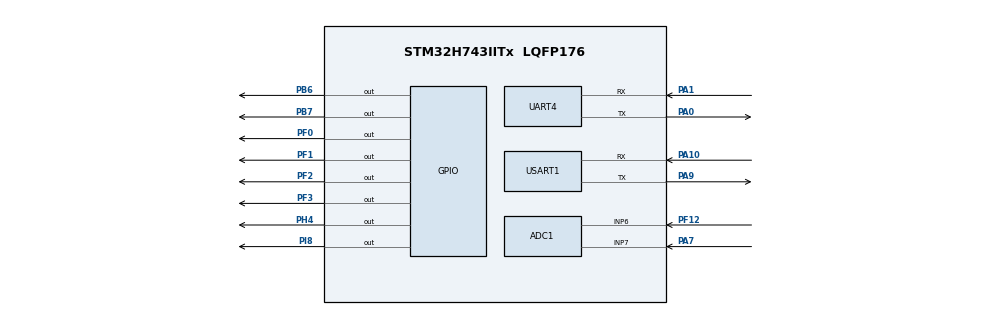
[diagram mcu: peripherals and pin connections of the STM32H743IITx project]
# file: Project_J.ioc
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ADC1.Channel-2\#ChannelRegularConversion=ADC_CHANNEL_6
ADC1.Channel-3\#ChannelRegularConversion=ADC_CHANNEL_7
ADC1.ContinuousConvMode=DISABLE
ADC1.DiscontinuousConvMode=ENABLE
ADC1.NbrOfConversion=2
ADC1.NbrOfConversionFlag=1
ADC1.NbrOfDiscConversion=1
ADC1.OffsetNumber-2\#ChannelRegularConversion=ADC_OFFSET_NONE
ADC1.OffsetNumber-3\#ChannelRegularConversion=ADC_OFFSET_NONE
ADC1.OffsetSignedSaturation-2\#ChannelRegularConversion=DISABLE
ADC1.OffsetSignedSaturation-3\#ChannelRegularConversion=DISABLE
ADC1.Rank-2\#ChannelRegularConversion=1
ADC1.Rank-3\#ChannelRegularConversion=2
ADC1.SamplingTime-2\#ChannelRegularConversion=ADC_SAMPLETIME_1CYCLE_5
ADC1.SamplingTime-3\#ChannelRegularConversion=ADC_SAMPLETIME_1CYCLE_5
ADC1.master=1
ADC3.Channel-1\#ChannelRegularConversion=ADC_CHANNEL_TEMPSENSOR
ADC3.Channel-2\#ChannelRegularConversion=ADC_CHANNEL_VBAT
ADC3.ContinuousConvMode=DISABLE
ADC3.DiscontinuousConvMode=ENABLE
ADC3.NbrOfConversion=2
ADC3.NbrOfConversionFlag=1
ADC3.NbrOfDiscConversion=1
ADC3.OffsetNumber-1\#ChannelRegularConversion=ADC_OFFSET_NONE
ADC3.OffsetNumber-2\#ChannelRegularConversion=ADC_OFFSET_NONE
ADC3.OffsetSignedSaturation-1\#ChannelRegularConversion=DISABLE
ADC3.OffsetSignedSaturation-2\#ChannelRegularConversion=DISABLE
ADC3.Rank-1\#ChannelRegularConversion=1
ADC3.Rank-2\#ChannelRegularConversion=2
ADC3.SamplingTime-1\#ChannelRegularConversion=ADC_SAMPLETIME_1CYCLE_5
ADC3.SamplingTime-2\#ChannelRegularConversion=ADC_SAMPLETIME_1CYCLE_5
CORTEX_M7.CPU_DCache=Enabled
CORTEX_M7.CPU_ICache=Enabled
Mcu.Family=STM32H7
Mcu.Name=STM32H743IITx
Mcu.Package=LQFP176
NVIC.PriorityGroup=NVIC_PRIORITYGROUP_4
NVIC.TIM15_IRQn=true\:14\:0\:true\:false\:true\:true\:true\:true
NVIC.TIM16_IRQn=true\:12\:0\:true\:false\:true\:true\:true\:true
NVIC.TIM17_IRQn=true\:13\:0\:true\:false\:true\:true\:true\:true
PA0.GPIO_Speed=GPIO_SPEED_FREQ_VERY_HIGH
PA0.Mode=Asynchronous
PA0.Signal=UART4_TX
PA1.GPIO_Speed=GPIO_SPEED_FREQ_VERY_HIGH
PA1.Mode=Asynchronous
PA1.Signal=UART4_RX
PA10.GPIO_Speed=GPIO_SPEED_FREQ_VERY_HIGH
PA10.Mode=Asynchronous
PA10.Signal=USART1_RX
PA13\ (JTMS/SWDIO).Mode=Serial_Wire
PA13\ (JTMS/SWDIO).Signal=DEBUG_JTMS-SWDIO
PA14\ (JTCK/SWCLK).Mode=Serial_Wire
PA14\ (JTCK/SWCLK).Signal=DEBUG_JTCK-SWCLK
PA7.Signal=ADCx_INP7
PA9.GPIO_Speed=GPIO_SPEED_FREQ_VERY_HIGH
PA9.Mode=Asynchronous
PA9.Signal=USART1_TX
PB6.Signal=GPIO_Output
PB7.Signal=GPIO_Output
PF0.Signal=GPIO_Output
PF1.Signal=GPIO_Output
PF12.Mode=IN6-Single-Ended
PF12.Signal=ADC1_INP6
PF2.Signal=GPIO_Output
PF3.Signal=GPIO_Output
PH4.Signal=GPIO_Output
PI8.Signal=GPIO_Output
ProjectManager.HeapSize=0x200
ProjectManager.StackSize=0x400
ProjectManager.TargetToolchain=Makefile
RCC.ADCFreq_Value=75000000
RCC.APB1Freq_Value=120000000
RCC.APB2Freq_Value=120000000
RCC.APB3Freq_Value=120000000
RCC.APB4Freq_Value=120000000
RCC.CortexFreq_Value=480000000
RCC.D1PPRE=RCC_APB3_DIV2
RCC.D2PPRE1=RCC_APB1_DIV2
RCC.D2PPRE2=RCC_APB2_DIV2
RCC.D3PPRE=RCC_APB4_DIV2
RCC.DIVM1=1
RCC.DIVM2=1
RCC.DIVM3=1
RCC.DIVN1=240
RCC.DIVN2=37
RCC.DIVN3=240
RCC.HCLKFreq_Value=240000000
RCC.HPRE=RCC_HCLK_DIV2
RCC.PLL2FRACN=4096
RCC.PLLSourceVirtual=RCC_PLLSOURCE_CSI
RCC.SYSCLKFreq_VALUE=480000000
RCC.SYSCLKSource=RCC_SYSCLKSOURCE_PLLCLK
RCC.USBFreq_Value=480000000
SH.ADCx_INP7.0=ADC1_INP7,IN7-Single-Ended
TIM15.Period=9999
TIM15.Prescaler=239
TIM16.Channel=TIM_CHANNEL_1
TIM16.Period=9
TIM16.Prescaler=23
TIM17.Channel=TIM_CHANNEL_1
TIM17.Period=999
TIM17.Prescaler=239
USART1.VirtualMode-Asynchronous=VM_ASYNC
VP_ADC3_TempSens_Input.Mode=IN-TempSens
VP_ADC3_Vbat_Input.Mode=IN-Vbat
VP_TIM15_VS_ClockSourceINT.Mode=Internal
VP_TIM16_VS_ClockSourceINT.Mode=Enable_Timer
VP_TIM16_VS_no_output1.Mode=Output Compare1 No Output
VP_TIM17_VS_ClockSourceINT.Mode=Enable_Timer
VP_TIM17_VS_no_output1.Mode=Output Compare1 No Output
board=custom

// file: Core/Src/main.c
/* USER CODE BEGIN Header */
/**
  ******************************************************************************
  * @file           : main.c
  * @brief          : Main program body
  ******************************************************************************
  * @attention
  *
  * Copyright (c) 2022 STMicroelectronics.
  * All rights reserved.
  *
  * This software is licensed under terms that can be found in the LICENSE file
  * in the root directory of this software component.
  * If no LICENSE file comes with this software, it is provided AS-IS.
  *
  ******************************************************************************
  */
/* USER CODE END Header */
#include "main.h"
#include "os.h"

ADC_HandleTypeDef hadc1;
ADC_HandleTypeDef hadc3;

TIM_HandleTypeDef htim15;
TIM_HandleTypeDef htim16;
TIM_HandleTypeDef htim17;

UART_HandleTypeDef huart4;
UART_HandleTypeDef huart1;

void SystemClock_Config(void);
void PeriphCommonClock_Config(void);
static void MX_GPIO_Init(void);
static void MX_TIM17_Init(void);
static void MX_TIM16_Init(void);
static void MX_TIM15_Init(void);
static void MX_ADC3_Init(void);
static void MX_ADC1_Init(void);
static void MX_UART4_Init(void);
static void MX_USART1_UART_Init(void);

char dummy[1];
int main(void)
{

  /* Enable I-Cache---------------------------------------------------------*/
  SCB_EnableICache();

  /* Enable D-Cache---------------------------------------------------------*/
  SCB_EnableDCache();

  /* MCU Configuration--------------------------------------------------------*/

  /* Reset of all peripherals, Initializes the Flash interface and the Systick. */
  HAL_Init();

  /* Configure the system clock */
  SystemClock_Config();

/* Configure the peripherals common clocks */
  PeriphCommonClock_Config();

  /* Initialize all configured peripherals */
  MX_GPIO_Init();
  MX_TIM17_Init();
  MX_TIM16_Init();
  MX_TIM15_Init();
  MX_ADC3_Init();
  MX_ADC1_Init();
  MX_UART4_Init();
  MX_USART1_UART_Init();
  /* USER CODE BEGIN 2 */
  HAL_TIM_Base_Start_IT(&htim15);
  HAL_TIM_Base_Start_IT(&htim16);
  HAL_TIM_Base_Start_IT(&htim17);

  HAL_GPIO_WritePin(GPIOF,GPIO_PIN_0,GPIO_PIN_SET);
  HAL_GPIO_WritePin(GPIOF,GPIO_PIN_1,GPIO_PIN_SET);
  HAL_Delay(100);
  HAL_UART_Receive_IT(&huart1, dummy, 1);
  HAL_UART_Receive_IT(&huart4, dummy, 1);
  HAL_UART_Receive_IT(&huart1, dummy, 1);
  HAL_UART_Receive_IT(&huart4, dummy, 1);
  HAL_Delay(1000);
  Os_Init_Task();
    /* USER CODE END 2 */
    /* Infinite loop */
    while (1)
    {
        /* USER CODE END WHILE */
        Os_Handler();
    }
}
void SystemClock_Config(void)
{
  RCC_OscInitTypeDef RCC_OscInitStruct = {0};
  RCC_ClkInitTypeDef RCC_ClkInitStruct = {0};

  /** Supply configuration update enable
  */
  HAL_PWREx_ConfigSupply(PWR_LDO_SUPPLY);

  /** Configure the main internal regulator output voltage
  */
  __HAL_PWR_VOLTAGESCALING_CONFIG(PWR_REGULATOR_VOLTAGE_SCALE1);

  while(!__HAL_PWR_GET_FLAG(PWR_FLAG_VOSRDY)) {}

  __HAL_RCC_SYSCFG_CLK_ENABLE();
  __HAL_PWR_VOLTAGESCALING_CONFIG(PWR_REGULATOR_VOLTAGE_SCALE0);

  while(!__HAL_PWR_GET_FLAG(PWR_FLAG_VOSRDY)) {}

  /** Macro to configure the PLL clock source
  */
  __HAL_RCC_PLL_PLLSOURCE_CONFIG(RCC_PLLSOURCE_CSI);

  /** Initializes the RCC Oscillators according to the specified parameters
  * in the RCC_OscInitTypeDef structure.
  */
  RCC_OscInitStruct.OscillatorType = RCC_OSCILLATORTYPE_CSI;
  RCC_OscInitStruct.CSIState = RCC_CSI_ON;
  RCC_OscInitStruct.CSICalibrationValue = RCC_CSICALIBRATION_DEFAULT;
  RCC_OscInitStruct.PLL.PLLState = RCC_PLL_ON;
  RCC_OscInitStruct.PLL.PLLSource = RCC_PLLSOURCE_CSI;
  RCC_OscInitStruct.PLL.PLLM = 1;
  RCC_OscInitStruct.PLL.PLLN = 240;
  RCC_OscInitStruct.PLL.PLLP = 2;
  RCC_OscInitStruct.PLL.PLLQ = 2;
  RCC_OscInitStruct.PLL.PLLR = 2;
  RCC_OscInitStruct.PLL.PLLRGE = RCC_PLL1VCIRANGE_2;
  RCC_OscInitStruct.PLL.PLLVCOSEL = RCC_PLL1VCOWIDE;
  RCC_OscInitStruct.PLL.PLLFRACN = 0;
  if (HAL_RCC_OscConfig(&RCC_OscInitStruct) != HAL_OK)
  {
    Error_Handler();
  }

  /** Initializes the CPU, AHB and APB buses clocks
  */
  RCC_ClkInitStruct.ClockType = RCC_CLOCKTYPE_HCLK|RCC_CLOCKTYPE_SYSCLK
                              |RCC_CLOCKTYPE_PCLK1|RCC_CLOCKTYPE_PCLK2
                              |RCC_CLOCKTYPE_D3PCLK1|RCC_CLOCKTYPE_D1PCLK1;
  RCC_ClkInitStruct.SYSCLKSource = RCC_SYSCLKSOURCE_PLLCLK;
  RCC_ClkInitStruct.SYSCLKDivider = RCC_SYSCLK_DIV1;
  RCC_ClkInitStruct.AHBCLKDivider = RCC_HCLK_DIV2;
  RCC_ClkInitStruct.APB3CLKDivider = RCC_APB3_DIV2;
  RCC_ClkInitStruct.APB1CLKDivider = RCC_APB1_DIV2;
  RCC_ClkInitStruct.APB2CLKDivider = RCC_APB2_DIV2;
  RCC_ClkInitStruct.APB4CLKDivider = RCC_APB4_DIV2;

  if (HAL_RCC_ClockConfig(&RCC_ClkInitStruct, FLASH_LATENCY_4) != HAL_OK)
  {
    Error_Handler();
  }
}

void PeriphCommonClock_Config(void)
{
  RCC_PeriphCLKInitTypeDef PeriphClkInitStruct = {0};

  /** Initializes the peripherals clock
  */
  PeriphClkInitStruct.PeriphClockSelection = RCC_PERIPHCLK_ADC;
  PeriphClkInitStruct.PLL2.PLL2M = 1;
  PeriphClkInitStruct.PLL2.PLL2N = 37;
  PeriphClkInitStruct.PLL2.PLL2P = 2;
  PeriphClkInitStruct.PLL2.PLL2Q = 2;
  PeriphClkInitStruct.PLL2.PLL2R = 2;
  PeriphClkInitStruct.PLL2.PLL2RGE = RCC_PLL2VCIRANGE_2;
  PeriphClkInitStruct.PLL2.PLL2VCOSEL = RCC_PLL2VCOMEDIUM;
  PeriphClkInitStruct.PLL2.PLL2FRACN = 4096;
  PeriphClkInitStruct.AdcClockSelection = RCC_ADCCLKSOURCE_PLL2;
  if (HAL_RCCEx_PeriphCLKConfig(&PeriphClkInitStruct) != HAL_OK)
  {
    Error_Handler();
  }
}

static void MX_ADC1_Init(void)
{

  ADC_MultiModeTypeDef multimode = {0};
  ADC_ChannelConfTypeDef sConfig = {0};

  /** Common config
  */
  hadc1.Instance = ADC1;
  hadc1.Init.ClockPrescaler = ADC_CLOCK_ASYNC_DIV1;
  hadc1.Init.Resolution = ADC_RESOLUTION_16B;
  hadc1.Init.ScanConvMode = ADC_SCAN_ENABLE;
  hadc1.Init.EOCSelection = ADC_EOC_SINGLE_CONV;
  hadc1.Init.LowPowerAutoWait = DISABLE;
  hadc1.Init.ContinuousConvMode = DISABLE;
  hadc1.Init.NbrOfConversion = 2;
  hadc1.Init.DiscontinuousConvMode = ENABLE;
  hadc1.Init.NbrOfDiscConversion = 1;
  hadc1.Init.ExternalTrigConv = ADC_SOFTWARE_START;
  hadc1.Init.ExternalTrigConvEdge = ADC_EXTERNALTRIGCONVEDGE_NONE;
  hadc1.Init.ConversionDataManagement = ADC_CONVERSIONDATA_DR;
  hadc1.Init.Overrun = ADC_OVR_DATA_PRESERVED;
  hadc1.Init.LeftBitShift = ADC_LEFTBITSHIFT_NONE;
  hadc1.Init.OversamplingMode = DISABLE;
  if (HAL_ADC_Init(&hadc1) != HAL_OK)
  {
    Error_Handler();
  }

  /** Configure the ADC multi-mode
  */
  multimode.Mode = ADC_MODE_INDEPENDENT;
  if (HAL_ADCEx_MultiModeConfigChannel(&hadc1, &multimode) != HAL_OK)
  {
    Error_Handler();
  }

  /** Configure Regular Channel
  */
  sConfig.Channel = ADC_CHANNEL_6;
  sConfig.Rank = ADC_REGULAR_RANK_1;
  sConfig.SamplingTime = ADC_SAMPLETIME_1CYCLE_5;
  sConfig.SingleDiff = ADC_SINGLE_ENDED;
  sConfig.OffsetNumber = ADC_OFFSET_NONE;
  sConfig.Offset = 0;
  sConfig.OffsetSignedSaturation = DISABLE;
  if (HAL_ADC_ConfigChannel(&hadc1, &sConfig) != HAL_OK)
  {
    Error_Handler();
  }

  /** Configure Regular Channel
  */
  sConfig.Channel = ADC_CHANNEL_7;
  sConfig.Rank = ADC_REGULAR_RANK_2;
  if (HAL_ADC_ConfigChannel(&hadc1, &sConfig) != HAL_OK)
  {
    Error_Handler();
  }

}

static void MX_ADC3_Init(void)
{

  ADC_ChannelConfTypeDef sConfig = {0};

  /** Common config
  */
  hadc3.Instance = ADC3;
  hadc3.Init.Resolution = ADC_RESOLUTION_16B;
  hadc3.Init.ScanConvMode = ADC_SCAN_ENABLE;
  hadc3.Init.EOCSelection = ADC_EOC_SINGLE_CONV;
  hadc3.Init.LowPowerAutoWait = DISABLE;
  hadc3.Init.ContinuousConvMode = DISABLE;
  hadc3.Init.NbrOfConversion = 2;
  hadc3.Init.DiscontinuousConvMode = ENABLE;
  hadc3.Init.NbrOfDiscConversion = 1;
  hadc3.Init.ExternalTrigConv = ADC_SOFTWARE_START;
  hadc3.Init.ExternalTrigConvEdge = ADC_EXTERNALTRIGCONVEDGE_NONE;
  hadc3.Init.ConversionDataManagement = ADC_CONVERSIONDATA_DR;
  hadc3.Init.Overrun = ADC_OVR_DATA_PRESERVED;
  hadc3.Init.LeftBitShift = ADC_LEFTBITSHIFT_NONE;
  hadc3.Init.OversamplingMode = DISABLE;
  if (HAL_ADC_Init(&hadc3) != HAL_OK)
  {
    Error_Handler();
  }

  /** Configure Regular Channel
  */
  sConfig.Channel = ADC_CHANNEL_TEMPSENSOR;
  sConfig.Rank = ADC_REGULAR_RANK_1;
  sConfig.SamplingTime = ADC_SAMPLETIME_1CYCLE_5;
  sConfig.SingleDiff = ADC_SINGLE_ENDED;
  sConfig.OffsetNumber = ADC_OFFSET_NONE;
  sConfig.Offset = 0;
  sConfig.OffsetSignedSaturation = DISABLE;
  if (HAL_ADC_ConfigChannel(&hadc3, &sConfig) != HAL_OK)
  {
    Error_Handler();
  }

  /** Configure Regular Channel
  */
  sConfig.Channel = ADC_CHANNEL_VBAT;
  sConfig.Rank = ADC_REGULAR_RANK_2;
  if (HAL_ADC_ConfigChannel(&hadc3, &sConfig) != HAL_OK)
  {
    Error_Handler();
  }

}

static void MX_TIM15_Init(void)
{

  TIM_ClockConfigTypeDef sClockSourceConfig = {0};
  TIM_MasterConfigTypeDef sMasterConfig = {0};

  htim15.Instance = TIM15;
  htim15.Init.Prescaler = 239;
  htim15.Init.CounterMode = TIM_COUNTERMODE_UP;
  htim15.Init.Period = 9999;
  htim15.Init.ClockDivision = TIM_CLOCKDIVISION_DIV1;
  htim15.Init.RepetitionCounter = 0;
  htim15.Init.AutoReloadPreload = TIM_AUTORELOAD_PRELOAD_DISABLE;
  if (HAL_TIM_Base_Init(&htim15) != HAL_OK)
  {
    Error_Handler();
  }
  sClockSourceConfig.ClockSource = TIM_CLOCKSOURCE_INTERNAL;
  if (HAL_TIM_ConfigClockSource(&htim15, &sClockSourceConfig) != HAL_OK)
  {
    Error_Handler();
  }
  sMasterConfig.MasterOutputTrigger = TIM_TRGO_RESET;
  sMasterConfig.MasterSlaveMode = TIM_MASTERSLAVEMODE_DISABLE;
  if (HAL_TIMEx_MasterConfigSynchronization(&htim15, &sMasterConfig) != HAL_OK)
  {
    Error_Handler();
  }

}

static void MX_TIM16_Init(void)
{

  TIM_OC_InitTypeDef sConfigOC = {0};
  TIM_BreakDeadTimeConfigTypeDef sBreakDeadTimeConfig = {0};

  htim16.Instance = TIM16;
  htim16.Init.Prescaler = 23;
  htim16.Init.CounterMode = TIM_COUNTERMODE_UP;
  htim16.Init.Period = 9;
  htim16.Init.ClockDivision = TIM_CLOCKDIVISION_DIV1;
  htim16.Init.RepetitionCounter = 0;
  htim16.Init.AutoReloadPreload = TIM_AUTORELOAD_PRELOAD_DISABLE;
  if (HAL_TIM_Base_Init(&htim16) != HAL_OK)
  {
    Error_Handler();
  }
  if (HAL_TIM_OC_Init(&htim16) != HAL_OK)
  {
    Error_Handler();
  }
  sConfigOC.OCMode = TIM_OCMODE_TIMING;
  sConfigOC.Pulse = 0;
  sConfigOC.OCPolarity = TIM_OCPOLARITY_HIGH;
  sConfigOC.OCNPolarity = TIM_OCNPOLARITY_HIGH;
  sConfigOC.OCFastMode = TIM_OCFAST_DISABLE;
  sConfigOC.OCIdleState = TIM_OCIDLESTATE_RESET;
  sConfigOC.OCNIdleState = TIM_OCNIDLESTATE_RESET;
  if (HAL_TIM_OC_ConfigChannel(&htim16, &sConfigOC, TIM_CHANNEL_1) != HAL_OK)
  {
    Error_Handler();
  }
  sBreakDeadTimeConfig.OffStateRunMode = TIM_OSSR_DISABLE;
  sBreakDeadTimeConfig.OffStateIDLEMode = TIM_OSSI_DISABLE;
  sBreakDeadTimeConfig.LockLevel = TIM_LOCKLEVEL_OFF;
  sBreakDeadTimeConfig.DeadTime = 0;
  sBreakDeadTimeConfig.BreakState = TIM_BREAK_DISABLE;
  sBreakDeadTimeConfig.BreakPolarity = TIM_BREAKPOLARITY_HIGH;
  sBreakDeadTimeConfig.BreakFilter = 0;
  sBreakDeadTimeConfig.AutomaticOutput = TIM_AUTOMATICOUTPUT_DISABLE;
  if (HAL_TIMEx_ConfigBreakDeadTime(&htim16, &sBreakDeadTimeConfig) != HAL_OK)
  {
    Error_Handler();
  }

}

static void MX_TIM17_Init(void)
{

  TIM_OC_InitTypeDef sConfigOC = {0};
  TIM_BreakDeadTimeConfigTypeDef sBreakDeadTimeConfig = {0};

  htim17.Instance = TIM17;
  htim17.Init.Prescaler = 239;
  htim17.Init.CounterMode = TIM_COUNTERMODE_UP;
  htim17.Init.Period = 999;
  htim17.Init.ClockDivision = TIM_CLOCKDIVISION_DIV1;
  htim17.Init.RepetitionCounter = 0;
  htim17.Init.AutoReloadPreload = TIM_AUTORELOAD_PRELOAD_DISABLE;
  if (HAL_TIM_Base_Init(&htim17) != HAL_OK)
  {
    Error_Handler();
  }
  if (HAL_TIM_OC_Init(&htim17) != HAL_OK)
  {
    Error_Handler();
  }
  sConfigOC.OCMode = TIM_OCMODE_TIMING;
  sConfigOC.Pulse = 0;
  sConfigOC.OCPolarity = TIM_OCPOLARITY_HIGH;
  sConfigOC.OCNPolarity = TIM_OCNPOLARITY_HIGH;
  sConfigOC.OCFastMode = TIM_OCFAST_DISABLE;
  sConfigOC.OCIdleState = TIM_OCIDLESTATE_RESET;
  sConfigOC.OCNIdleState = TIM_OCNIDLESTATE_RESET;
  if (HAL_TIM_OC_ConfigChannel(&htim17, &sConfigOC, TIM_CHANNEL_1) != HAL_OK)
  {
    Error_Handler();
  }
  sBreakDeadTimeConfig.OffStateRunMode = TIM_OSSR_DISABLE;
  sBreakDeadTimeConfig.OffStateIDLEMode = TIM_OSSI_DISABLE;
  sBreakDeadTimeConfig.LockLevel = TIM_LOCKLEVEL_OFF;
  sBreakDeadTimeConfig.DeadTime = 0;
  sBreakDeadTimeConfig.BreakState = TIM_BREAK_DISABLE;
  sBreakDeadTimeConfig.BreakPolarity = TIM_BREAKPOLARITY_HIGH;
  sBreakDeadTimeConfig.BreakFilter = 0;
  sBreakDeadTimeConfig.AutomaticOutput = TIM_AUTOMATICOUTPUT_DISABLE;
  if (HAL_TIMEx_ConfigBreakDeadTime(&htim17, &sBreakDeadTimeConfig) != HAL_OK)
  {
    Error_Handler();
  }

}

static void MX_UART4_Init(void)
{

  huart4.Instance = UART4;
  huart4.Init.BaudRate = 115200;
  huart4.Init.WordLength = UART_WORDLENGTH_8B;
  huart4.Init.StopBits = UART_STOPBITS_1;
  huart4.Init.Parity = UART_PARITY_NONE;
  huart4.Init.Mode = UART_MODE_TX_RX;
  huart4.Init.HwFlowCtl = UART_HWCONTROL_NONE;
  huart4.Init.OverSampling = UART_OVERSAMPLING_16;
  huart4.Init.OneBitSampling = UART_ONE_BIT_SAMPLE_DISABLE;
  huart4.Init.ClockPrescaler = UART_PRESCALER_DIV1;
  huart4.AdvancedInit.AdvFeatureInit = UART_ADVFEATURE_NO_INIT;
  if (HAL_UART_Init(&huart4) != HAL_OK)
  {
    Error_Handler();
  }
  if (HAL_UARTEx_SetTxFifoThreshold(&huart4, UART_TXFIFO_THRESHOLD_1_8) != HAL_OK)
  {
    Error_Handler();
  }
  if (HAL_UARTEx_SetRxFifoThreshold(&huart4, UART_RXFIFO_THRESHOLD_1_8) != HAL_OK)
  {
    Error_Handler();
  }
  if (HAL_UARTEx_DisableFifoMode(&huart4) != HAL_OK)
  {
    Error_Handler();
  }

}

static void MX_USART1_UART_Init(void)
{

  huart1.Instance = USART1;
  huart1.Init.BaudRate = 115200;
  huart1.Init.WordLength = UART_WORDLENGTH_8B;
  huart1.Init.StopBits = UART_STOPBITS_1;
  huart1.Init.Parity = UART_PARITY_NONE;
  huart1.Init.Mode = UART_MODE_TX_RX;
  huart1.Init.HwFlowCtl = UART_HWCONTROL_NONE;
  huart1.Init.OverSampling = UART_OVERSAMPLING_16;
  huart1.Init.OneBitSampling = UART_ONE_BIT_SAMPLE_DISABLE;
  huart1.Init.ClockPrescaler = UART_PRESCALER_DIV1;
  huart1.AdvancedInit.AdvFeatureInit = UART_ADVFEATURE_NO_INIT;
  if (HAL_UART_Init(&huart1) != HAL_OK)
  {
    Error_Handler();
  }
  if (HAL_UARTEx_SetTxFifoThreshold(&huart1, UART_TXFIFO_THRESHOLD_1_8) != HAL_OK)
  {
    Error_Handler();
  }
  if (HAL_UARTEx_SetRxFifoThreshold(&huart1, UART_RXFIFO_THRESHOLD_1_8) != HAL_OK)
  {
    Error_Handler();
  }
  if (HAL_UARTEx_DisableFifoMode(&huart1) != HAL_OK)
  {
    Error_Handler();
  }

}

static void MX_GPIO_Init(void)
{
  GPIO_InitTypeDef GPIO_InitStruct = {0};

  /* GPIO Ports Clock Enable */
  __HAL_RCC_GPIOI_CLK_ENABLE();
  __HAL_RCC_GPIOF_CLK_ENABLE();
  __HAL_RCC_GPIOA_CLK_ENABLE();
  __HAL_RCC_GPIOH_CLK_ENABLE();
  __HAL_RCC_GPIOB_CLK_ENABLE();

  /*Configure GPIO pin Output Level */
  HAL_GPIO_WritePin(GPIOI, GPIO_PIN_8, GPIO_PIN_RESET);

  /*Configure GPIO pin Output Level */
  HAL_GPIO_WritePin(GPIOF, GPIO_PIN_0|GPIO_PIN_1|GPIO_PIN_2|GPIO_PIN_3, GPIO_PIN_RESET);

  /*Configure GPIO pin Output Level */
  HAL_GPIO_WritePin(GPIOH, GPIO_PIN_4, GPIO_PIN_RESET);

  /*Configure GPIO pin Output Level */
  HAL_GPIO_WritePin(GPIOB, GPIO_PIN_6|GPIO_PIN_7, GPIO_PIN_RESET);

  /*Configure GPIO pin : PI8 */
  GPIO_InitStruct.Pin = GPIO_PIN_8;
  GPIO_InitStruct.Mode = GPIO_MODE_OUTPUT_PP;
  GPIO_InitStruct.Pull = GPIO_NOPULL;
  GPIO_InitStruct.Speed = GPIO_SPEED_FREQ_LOW;
  HAL_GPIO_Init(GPIOI, &GPIO_InitStruct);

  /*Configure GPIO pins : PF0 PF1 PF2 PF3 */
  GPIO_InitStruct.Pin = GPIO_PIN_0|GPIO_PIN_1|GPIO_PIN_2|GPIO_PIN_3;
  GPIO_InitStruct.Mode = GPIO_MODE_OUTPUT_PP;
  GPIO_InitStruct.Pull = GPIO_NOPULL;
  GPIO_InitStruct.Speed = GPIO_SPEED_FREQ_LOW;
  HAL_GPIO_Init(GPIOF, &GPIO_InitStruct);

  /*Configure GPIO pin : PH4 */
  GPIO_InitStruct.Pin = GPIO_PIN_4;
  GPIO_InitStruct.Mode = GPIO_MODE_OUTPUT_PP;
  GPIO_InitStruct.Pull = GPIO_NOPULL;
  GPIO_InitStruct.Speed = GPIO_SPEED_FREQ_LOW;
  HAL_GPIO_Init(GPIOH, &GPIO_InitStruct);

  /*Configure GPIO pins : PB6 PB7 */
  GPIO_InitStruct.Pin = GPIO_PIN_6|GPIO_PIN_7;
  GPIO_InitStruct.Mode = GPIO_MODE_OUTPUT_PP;
  GPIO_InitStruct.Pull = GPIO_NOPULL;
  GPIO_InitStruct.Speed = GPIO_SPEED_FREQ_LOW;
  HAL_GPIO_Init(GPIOB, &GPIO_InitStruct);

}

void Error_Handler(void)
{
  __disable_irq();
  while (1)
  {
  }
}
